# STM32WBAxx register map
File version: 0.1
Registers are 32-bit, read-write, reset 0x0 unless marked. A register's access mark holds for its fields unless they carry their own. Offsets are from the block's base; [hi:lo] are bit positions; {n}, {i} and the like mark numbered series.

## TIM16 — General purpose timers
Base 0x40014400
Same registers: TIM17 0x40014800, SEC_TIM16 0x50014400, SEC_TIM17 0x50014800
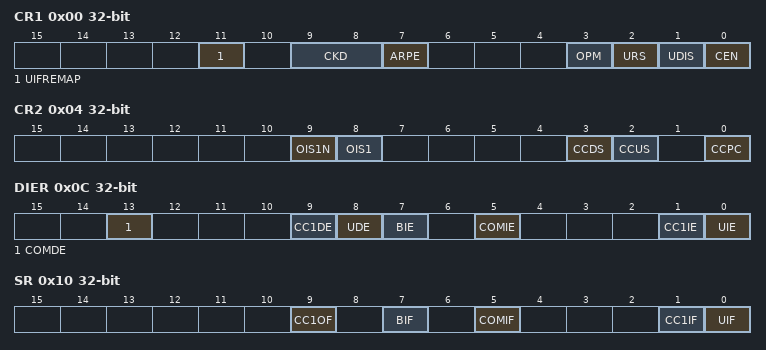
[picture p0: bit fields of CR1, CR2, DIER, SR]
0x00 CR1 — control register 1
  [11] UIFREMAP — UIF status bit remapping
  [9:8] CKD — Clock division
  [7] ARPE — Auto-reload preload enable
  [3] OPM — One pulse mode
  [2] URS — Update request source
  [1] UDIS — Update disable
  [0] CEN — Counter enable
0x04 CR2 — control register 2
  [9] OIS1N — Output Idle state 1
  [8] OIS1 — Output Idle state 1
  [3] CCDS — Capture/compare DMA selection
  [2] CCUS — Capture/compare control update selection
  [0] CCPC — Capture/compare preloaded control
0x0C DIER — DMA/interrupt enable register
  [13] COMDE — COM DMA request enable
  [9] CC1DE — Capture/Compare 1 DMA request enable
  [8] UDE — Update DMA request enable
  [7] BIE — Break interrupt enable
  [5] COMIE — COM interrupt enable
  [1] CC1IE — Capture/Compare 1 interrupt enable
  [0] UIE — Update interrupt enable
0x10 SR — status register
  [9] CC1OF
  [7] BIF — Break interrupt flag
  [5] COMIF — COM interrupt flag
  [1] CC1IF — Capture/Compare 1 interrupt flag
  [0] UIF — Update interrupt flag
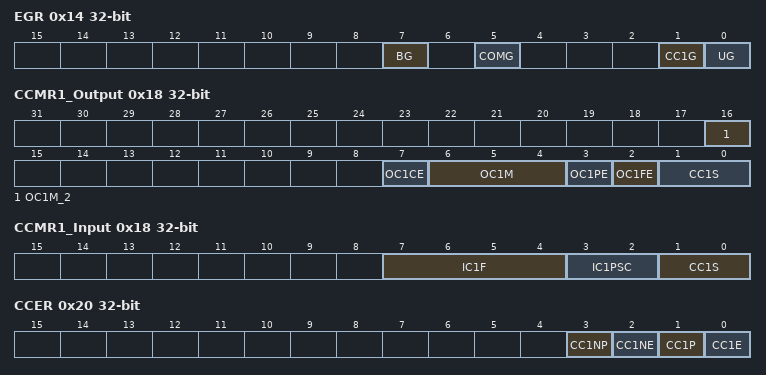
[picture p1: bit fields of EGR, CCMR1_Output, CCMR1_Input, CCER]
0x14 EGR wo — event generation register
  [7] BG — Break generation
  [5] COMG — Capture/Compare control update generation
  [1] CC1G — Capture/compare 1 generation
  [0] UG — Update generation
0x18 CCMR1_Output — capture/compare mode register (output mode)
  [16] OC1M_2 — Output Compare 1 mode
  [7] OC1CE — Output Compare 1 clear enable
  [6:4] OC1M — Output Compare 1 mode
  [3] OC1PE — Output Compare 1 preload enable
  [2] OC1FE — Output Compare 1 fast enable
  [1:0] CC1S — Capture/Compare 1 selection
0x18 CCMR1_Input (alternate view of CCMR1_Output) — capture/compare mode register 1 (input mode)
  [7:4] IC1F — Input capture 1 filter
  [3:2] IC1PSC — Input capture 1 prescaler
  [1:0] CC1S — Capture/Compare 1 selection
0x20 CCER — capture/compare enable register
  [3] CC1NP — Capture/Compare 1 output Polarity
  [2] CC1NE — Capture/Compare 1 complementary output enable
  [1] CC1P — Capture/Compare 1 output Polarity
  [0] CC1E — Capture/Compare 1 output enable
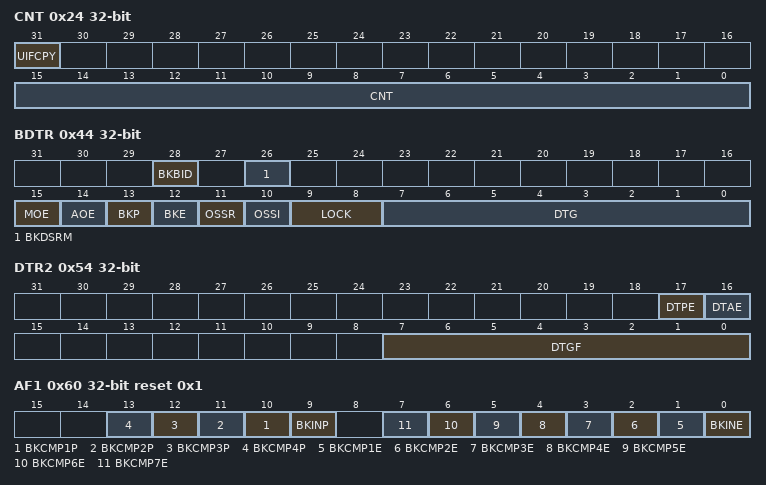
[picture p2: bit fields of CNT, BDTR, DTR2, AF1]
0x24 CNT access per field — counter
  [31] UIFCPY ro — UIF Copy
  [15:0] CNT rw
0x28 PSC — prescaler
  [15:0] PSC — Prescaler value
0x2C ARR reset 0xFFFF — auto-reload register
  [19:0] ARR — Auto-reload value
0x30 RCR — repetition counter register
  [7:0] REP — Repetition counter value
0x34 CCR1 — capture/compare register 1
  [19:0] CCR1 — Capture/Compare 1 value
0x44 BDTR — break and dead-time register
  [28] BKBID — Break Bidirectional
  [26] BKDSRM — Break Disarm
  [15] MOE — Main output enable
  [14] AOE — Automatic output enable
  [13] BKP — Break polarity
  [12] BKE — Break enable
  [11] OSSR — Off-state selection for Run mode
  [10] OSSI — Off-state selection for Idle mode
  [9:8] LOCK — Lock configuration
  [7:0] DTG — Dead-time generator setup
0x54 DTR2 — timer deadtime register 2
  [17] DTPE — Deadtime preload enable
  [16] DTAE — Deadtime asymmetric enable
  [7:0] DTGF — Deadtime asymmetric enable
0x5C TISEL — TIM17 option register 1
  [3:0] TI1SEL — selects tim_ti1_in[0..15] input
0x60 AF1 reset 0x1 — alternate function register 1
  [n+9] BKCMP{n}P (n=1..4) — tim_brk_cmp{n} input polarity
  [9] BKINP — TIMx_BKIN input polarity
  [n] BKCMP{n}E (n=1..7) — tim_brk_cmp{n} enable
  [0] BKINE — TIMx_BKIN input enable
0x64 AF2 reset 0x1 — alternate function register 2
  [18:16] OCRSEL — tim_ocref_clr source selection
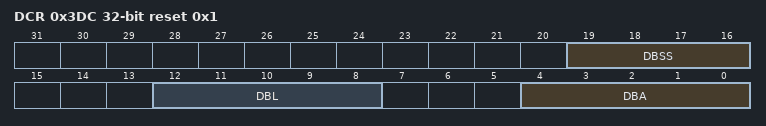
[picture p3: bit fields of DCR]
0x3DC DCR reset 0x1 — DMA control register
  [19:16] DBSS — DMA burst source selection
  [12:8] DBL — DMA burst length
  [4:0] DBA — DMA base address
0x3E0 DMAR reset 0x1 — TIM17 option register 1
  [31:0] DMAB — DMA register for burst accesses

## TIM6 — General-purpose-timers
Base 0x40001000
Same registers: TIM7 0x40001400, SEC_TIM6 0x50001000, SEC_TIM7 0x50001400
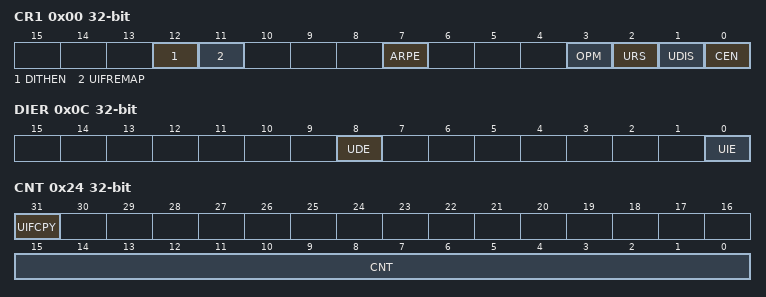
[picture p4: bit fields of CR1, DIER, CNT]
0x00 CR1 — control register 1
  [12] DITHEN — Dithering Enable
  [11] UIFREMAP — UIF status bit remapping
  [7] ARPE — Auto-reload preload enable
  [3] OPM — One-pulse mode
  [2] URS — Update request source
  [1] UDIS — Update disable
  [0] CEN — Counter enable
0x04 CR2 — control register 2
  [6:4] MMS — Master mode selection
0x0C DIER — DMA/Interrupt enable register
  [8] UDE, [0] UIE
0x10 SR — status register
  [0] UIF
0x14 EGR wo — event generation register
  [0] UG
0x24 CNT — counter
  [31] UIFCPY, [15:0] CNT
0x28 PSC — prescaler
  [15:0] PSC
0x2C ARR reset 0xFFFF — auto-reload register
  [18:0] ARR
